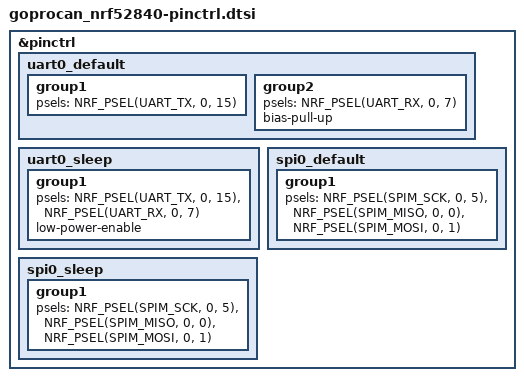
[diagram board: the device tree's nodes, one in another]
&pinctrl {
   /* configuration for uart0 device, default state */
   uart0_default: uart0_default {
     /* group 1 ('group1' name is arbitrary) */
     group1 {
       psels = <NRF_PSEL(UART_TX, 0, 15)>;
     };
     /* group 2 */
     group2 {
       psels = <NRF_PSEL(UART_RX, 0, 7)>;
       bias-pull-up;
     };
   };
   /* configuration for uart0 device, sleep state */
   uart0_sleep: uart0_sleep {
     /* group 1 ('group1' name is arbitrary) */
     group1 {
       /* configure P0.1 as UART_TX, P0.2 as UART_RTS P0.3 as UART_RX and
        * P0.4 as UART_CTS
        */
       psels = <NRF_PSEL(UART_TX, 0, 15)>,<NRF_PSEL(UART_RX, 0, 7)>;
       /* all pins are configured in low power mode */
       low-power-enable;
     };
   };
   
    spi0_default: spi0_default {                 
        group1{
          psels = <NRF_PSEL(SPIM_SCK, 0, 5)>, <NRF_PSEL(SPIM_MISO, 0, 0)>, <NRF_PSEL(SPIM_MOSI, 0, 1)>;
        };
    };

    spi0_sleep: spi0_sleep {
        group1{
          psels = <NRF_PSEL(SPIM_SCK, 0, 5)>, <NRF_PSEL(SPIM_MISO, 0, 0)>, <NRF_PSEL(SPIM_MOSI, 0, 1)>;
    };
    };
    
 
};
